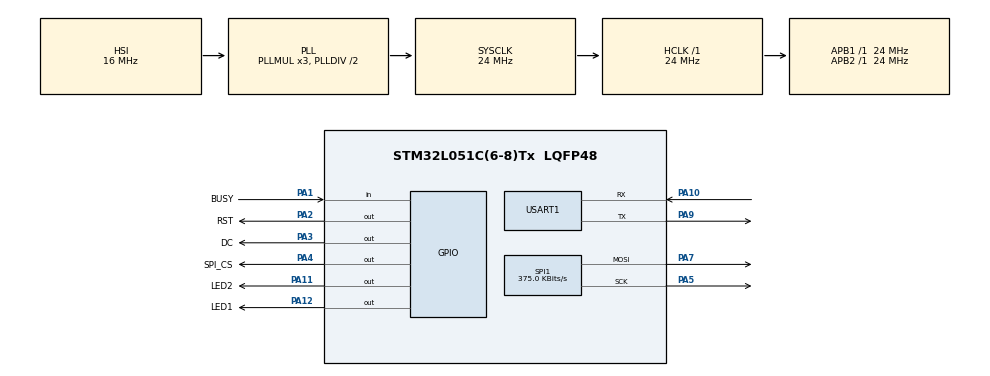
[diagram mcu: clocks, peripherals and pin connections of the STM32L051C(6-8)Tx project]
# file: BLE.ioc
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Mcu.Family=STM32L0
Mcu.Name=STM32L051C(6-8)Tx
Mcu.Package=LQFP48
NVIC.SPI1_IRQn=true\:0\:0\:false\:false\:true\:true\:true
NVIC.USART1_IRQn=true\:0\:0\:false\:false\:true\:true\:true
PA1.GPIO_Label=BUSY
PA1.Signal=GPIO_Input
PA10.Mode=Asynchronous
PA10.Signal=USART1_RX
PA11.GPIO_Label=LED2
PA11.Signal=GPIO_Output
PA12.GPIO_Label=LED1
PA12.Signal=GPIO_Output
PA13.Mode=Serial_Wire
PA13.Signal=SYS_SWDIO
PA14.Mode=Serial_Wire
PA14.Signal=SYS_SWCLK
PA2.GPIO_Label=RST
PA2.Signal=GPIO_Output
PA3.GPIO_Label=DC
PA3.Signal=GPIO_Output
PA4.GPIO_Label=SPI_CS
PA4.Signal=GPIO_Output
PA5.Mode=TX_Only_Simplex_Unidirect_Master
PA5.Signal=SPI1_SCK
PA7.Mode=TX_Only_Simplex_Unidirect_Master
PA7.Signal=SPI1_MOSI
PA9.Mode=Asynchronous
PA9.Signal=USART1_TX
ProjectManager.HeapSize=0x1400
ProjectManager.StackSize=0x400
ProjectManager.TargetToolchain=MDK-ARM V5.27
RCC.ADCFreq_Value=16000000
RCC.AHBFreq_Value=24000000
RCC.APB1Freq_Value=24000000
RCC.APB1TimFreq_Value=24000000
RCC.APB2Freq_Value=24000000
RCC.APB2TimFreq_Value=24000000
RCC.HCLKFreq_Value=24000000
RCC.HSE_VALUE=8000000
RCC.HSI16_VALUE=16000000
RCC.HSI_VALUE=16000000
RCC.LSE_VALUE=32768
RCC.MSI_VALUE=2097000
RCC.SYSCLKFreq_VALUE=24000000
RCC.SYSCLKSource=RCC_SYSCLKSOURCE_PLLCLK
RCC.VCOOutputFreq_Value=48000000
SPI1.BaudRatePrescaler=SPI_BAUDRATEPRESCALER_64
SPI1.CalculateBaudRate=375.0 KBits/s
SPI1.Direction=SPI_DIRECTION_2LINES
SPI1.Mode=SPI_MODE_MASTER
SPI1.VirtualType=VM_MASTER
USART1.VirtualMode-Asynchronous=VM_ASYNC
board=custom

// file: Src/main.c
/* USER CODE BEGIN Header */
/**
  ******************************************************************************
  * @file           : main.c
  * @brief          : Main program body
  ******************************************************************************
  * @attention
  *
  * <h2><center>&copy; Copyright (c) 2019 STMicroelectronics.
  * All rights reserved.</center></h2>
  *
  * This software component is licensed by ST under BSD 3-Clause license,
  * the "License"; You may not use this file except in compliance with the
  * License. You may obtain a copy of the License at:
  *                        opensource.org/licenses/BSD-3-Clause
  *
  ******************************************************************************
  */
/* USER CODE END Header */

#include "main.h"
#include "spi.h"
#include "usart.h"
#include "gpio.h"

/* USER CODE BEGIN Includes */
#include "DEV_Config.h"
#include "GUI_Paint.h"
#include "Debug.h"
#include "EPD_Test.h"
/* USER CODE END Includes */

void SystemClock_Config(void);

int main(void)
{

  /* MCU Configuration--------------------------------------------------------*/

  /* Reset of all peripherals, Initializes the Flash interface and the Systick. */
  HAL_Init();

  /* Configure the system clock */
  SystemClock_Config();

  /* Initialize all configured peripherals */
  MX_GPIO_Init();
  MX_SPI1_Init();
  MX_USART1_UART_Init();
  /* USER CODE BEGIN 2 */
	Check_RX_buffer_Initialization();
  	HAL_UART_Receive_IT(&huart1, (uint8_t *)&RX_temp, 1);		//enable uart1 receive

  /* USER CODE END 2 */

  /* Infinite loop */
  while (1)
  {

    /* USER CODE BEGIN 3 */
	  if(RX_sta == 4){
		  printf("RX: %s\r\n", RX_buff_origin+3);
		  printf("LEN: %d\r\n", RX_len);
	//	  EPD_1in54_V2_test();
		  RX_sta = 0;
	  }
  }
  /* USER CODE END 3 */
}

void SystemClock_Config(void)
{
  RCC_OscInitTypeDef RCC_OscInitStruct = {0};
  RCC_ClkInitTypeDef RCC_ClkInitStruct = {0};
  RCC_PeriphCLKInitTypeDef PeriphClkInit = {0};

  /** Configure the main internal regulator output voltage
  */
  __HAL_PWR_VOLTAGESCALING_CONFIG(PWR_REGULATOR_VOLTAGE_SCALE1);
  /** Initializes the CPU, AHB and APB busses clocks
  */
  RCC_OscInitStruct.OscillatorType = RCC_OSCILLATORTYPE_HSI;
  RCC_OscInitStruct.HSIState = RCC_HSI_ON;
  RCC_OscInitStruct.HSICalibrationValue = RCC_HSICALIBRATION_DEFAULT;
  RCC_OscInitStruct.PLL.PLLState = RCC_PLL_ON;
  RCC_OscInitStruct.PLL.PLLSource = RCC_PLLSOURCE_HSI;
  RCC_OscInitStruct.PLL.PLLMUL = RCC_PLLMUL_3;
  RCC_OscInitStruct.PLL.PLLDIV = RCC_PLLDIV_2;
  if (HAL_RCC_OscConfig(&RCC_OscInitStruct) != HAL_OK)
  {
    Error_Handler();
  }
  /** Initializes the CPU, AHB and APB busses clocks
  */
  RCC_ClkInitStruct.ClockType = RCC_CLOCKTYPE_HCLK|RCC_CLOCKTYPE_SYSCLK
                              |RCC_CLOCKTYPE_PCLK1|RCC_CLOCKTYPE_PCLK2;
  RCC_ClkInitStruct.SYSCLKSource = RCC_SYSCLKSOURCE_PLLCLK;
  RCC_ClkInitStruct.AHBCLKDivider = RCC_SYSCLK_DIV1;
  RCC_ClkInitStruct.APB1CLKDivider = RCC_HCLK_DIV1;
  RCC_ClkInitStruct.APB2CLKDivider = RCC_HCLK_DIV1;

  if (HAL_RCC_ClockConfig(&RCC_ClkInitStruct, FLASH_LATENCY_1) != HAL_OK)
  {
    Error_Handler();
  }
  PeriphClkInit.PeriphClockSelection = RCC_PERIPHCLK_USART1;
  PeriphClkInit.Usart1ClockSelection = RCC_USART1CLKSOURCE_PCLK2;
  if (HAL_RCCEx_PeriphCLKConfig(&PeriphClkInit) != HAL_OK)
  {
    Error_Handler();
  }
}

void Error_Handler(void)
{
}

/************************ (C) COPYRIGHT STMicroelectronics *****END OF FILE****/
